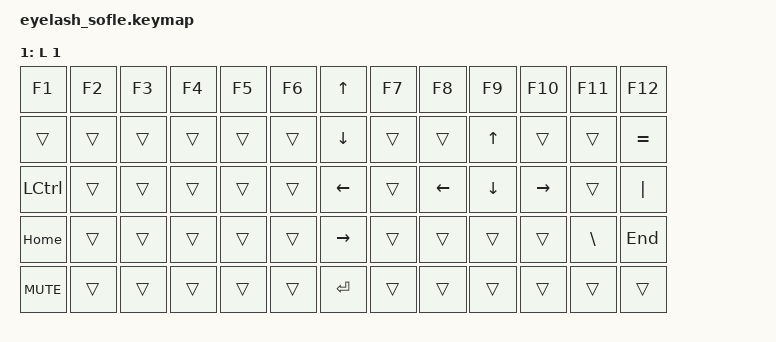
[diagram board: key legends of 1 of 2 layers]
#define ZMK_POINTING_DEFAULT_MOVE_VAL 1200  // 600
#define ZMK_POINTING_DEFAULT_SCRL_VAL 25   // 10

#include <input/processors.dtsi>
#include <zephyr/dt-bindings/input/input-event-codes.h>
#include <behaviors.dtsi>
#include <dt-bindings/zmk/bt.h>
#include <dt-bindings/zmk/ext_power.h>
#include <dt-bindings/zmk/keys.h>
#include <dt-bindings/zmk/pointing.h>
#include <dt-bindings/zmk/rgb.h>
#include <dt-bindings/zmk/outputs.h>

&mmv_input_listener { input-processors = <&zip_xy_scaler 2 1>; };

&msc_input_listener { input-processors = <&zip_scroll_scaler 2 1>; };

&msc {
    acceleration-exponent = <1>;      // 0
    time-to-max-speed-ms = <100>;       // 300
    delay-ms = <0>;                   // 0
};

&mmv {
    time-to-max-speed-ms = <500>;
    acceleration-exponent = <1>;
    trigger-period-ms = <16>;
};


/ {

    scroll_encoder: scroll_encoder {
        compatible = "zmk,behavior-sensor-rotate";
        #sensor-binding-cells = <0>;
        bindings = <&msc SCRL_DOWN>, <&msc SCRL_UP>;
        tap-ms = <100>;
    };

    keymap {
        compatible = "zmk,keymap";

        layer0 {
// ------------------------------------------------------------------------------------------------------------
// |  ESC  |  1  |  2  |  3   |  4   |  5   |                   |  6   |  7    |  8    |  9   |   0   |   `   |
// |  TAB  |  Q  |  W  |  E   |  R   |  T   |             ^     |  Y   |  U    |  I    |  O   |   P   |   -   |
// |  CTRL |  A  |  S  |  D   |  F   |  G   |        <- ENTER ->|  H   |  J    |  K    |  L   |   ;   |   '   |
// | SHIFT |  Z  |  X  |  C   |  V   |  B   |  Mute |     v     |  N   |  M    |  ,    |  .   |   /   | SHIFT |
//           | ALT  |   "["  | LOWER|  DEL |  SPACE |       | ENTER | BSPC | RAISE |  "]"  |  GUI  |
            bindings = <
&kp ESC   &kp N1 &kp N2 &kp N3   &kp N4   &kp N5       &kp UP_ARROW   &kp N6   &kp N7   &kp N8    &kp N9  &kp N0   &kp GRAVE
&kp TAB   &kp Q  &kp W  &kp E    &kp R    &kp T        &kp DOWN_ARROW &kp Y    &kp U    &kp I     &kp O   &kp P    &kp MINUS
&kp LCTRL &kp A  &kp S  &kp D    &kp F    &kp G       &kp LEFT_ARROW  &kp H    &kp J    &kp K     &kp L   &kp SEMI &kp SQT
&kp LSHFT &kp Z  &kp X  &kp C    &kp V    &kp B      &kp RIGHT_ARROW  &kp N    &kp M    &kp COMMA &kp DOT &kp FSLH &kp RSHFT
 &kp C_MUTE  &kp LALT  &kp LBKT  &mo 1  &kp DEL &kp SPACE     &kp ENTER   &kp RET  &kp BSPC &mo 1  &kp RBKT  &kp RGUI
            >;

            sensor-bindings = <&inc_dec_kp C_VOLUME_UP C_VOL_DN>;
            display-name = "L 0";
        };
        

        // &mo 1
        layer_1 {
// ------------------------------------------------------------------------------------------------------------
// |  F1   |  F2 |  F3 |  F4  |  F5  |  F6  |                   |  F7  |  F8   |  F9   |  F10 |  F11  |  F12  |
// |       |     |     |      |      |      |             ^     |      |       |   ^   |      |       |   =   |
// | CTRL  |     |     |      |      |      |        <- ENTER ->|      |  <-   |   v   |  ->  |       |   |   |
// | HOME  |     |     |      |      |      |  Mute  |    v     |      |       |       |      |   \   |  END  |
//                     |      |      |      |        |          |      |       |       |

            bindings = <
&kp F1     &kp F2           &kp F3            &kp F4            &kp F5       &kp F6           &kp UP_ARROW     &kp F7    &kp F8    &kp F9    &kp F10   &kp F11   &kp F12
&trans     &trans           &trans            &trans            &trans       &trans           &kp DOWN_ARROW     &trans    &trans    &kp UP    &trans    &trans    &kp EQUAL
&kp LCTRL  &trans           &trans            &trans            &trans       &trans           &kp LEFT_ARROW     &trans    &kp LEFT  &kp DOWN  &kp RIGHT &trans    &kp PIPE
&kp HOME   &trans           &trans            &trans            &trans       &trans           &kp RIGHT_ARROW    &trans    &trans    &trans    &trans    &kp BSLH  &kp END
&kp C_MUTE &trans          &trans             &trans            &trans       &trans          &kp ENTER           &trans    &trans    &trans    &trans    &trans    &trans
            >;

            display-name = "L 1";
            sensor-bindings = <&scroll_encoder>;
        };
    };
};
